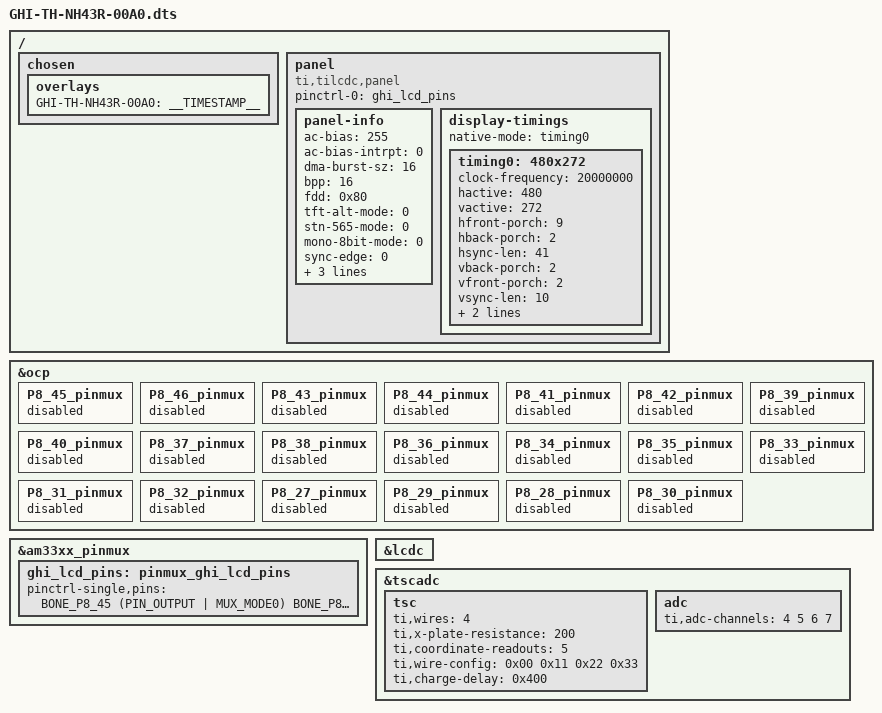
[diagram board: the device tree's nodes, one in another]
/*
 * Copyright (C) 2012 Texas Instruments Incorporated - http://www.ti.com/
 * Copyright (C) 2016 GHI Electronics, LLC - http://www.ghielectronics.com/ 
 *
 * This program is free software; you can redistribute it and/or modify
 * it under the terms of the GNU General Public License version 2 as
 * published by the Free Software Foundation.
 */

/dts-v1/;
/plugin/;

#include <dt-bindings/gpio/gpio.h>
#include <dt-bindings/pinctrl/am33xx.h>
#include <dt-bindings/board/am335x-bbw-bbb-base.h>

/ {
	/*
	 * Helper to show loaded overlays under: /proc/device-tree/chosen/overlays/
	 */
	fragment@0 {
		target-path="/";
		__overlay__ {

			chosen {
				overlays {
					GHI-TH-NH43R-00A0 = __TIMESTAMP__;
				};
			};
		};
	};

	/*
	 * Free up the pins used by the cape from the pinmux helpers.
	 */
	fragment@1 {
		target = <&ocp>;
		__overlay__ {
			P8_45_pinmux { status = "disabled"; };	/* P8_45: lcd_data0.lcd_data0 */
			P8_46_pinmux { status = "disabled"; };	/* P8_46: lcd_data1.lcd_data1 */
			P8_43_pinmux { status = "disabled"; };	/* P8_43: lcd_data2.lcd_data2 */
			P8_44_pinmux { status = "disabled"; };	/* P8_44: lcd_data3.lcd_data3 */
			P8_41_pinmux { status = "disabled"; };	/* P8_41: lcd_data4.lcd_data4 */
			P8_42_pinmux { status = "disabled"; };	/* P8_42: lcd_data5.lcd_data5 */
			P8_39_pinmux { status = "disabled"; };	/* P8_39: lcd_data6.lcd_data6 */
			P8_40_pinmux { status = "disabled"; };	/* P8_40: lcd_data7.lcd_data7 */
			P8_37_pinmux { status = "disabled"; };	/* P8_37: lcd_data8.lcd_data8 */
			P8_38_pinmux { status = "disabled"; };	/* P8_38: lcd_data9.lcd_data9 */
			P8_36_pinmux { status = "disabled"; };	/* P8_36: lcd_data10.lcd_data10 */
			P8_34_pinmux { status = "disabled"; };	/* P8_34: lcd_data11.lcd_data11 */
			P8_35_pinmux { status = "disabled"; };	/* P8_35: lcd_data12.lcd_data12 */
			P8_33_pinmux { status = "disabled"; };	/* P8_33: lcd_data13.lcd_data13 */
			P8_31_pinmux { status = "disabled"; };	/* P8_31: lcd_data14.lcd_data14 */
			P8_32_pinmux { status = "disabled"; };	/* P8_32: lcd_data15.lcd_data15 */

			P8_27_pinmux { status = "disabled"; };	/* P8_27: lcd_vsync.lcd_vsync */
			P8_29_pinmux { status = "disabled"; };	/* P8_29: lcd_hsync.lcd_hsync */
			P8_28_pinmux { status = "disabled"; };	/* P8_28: lcd_pclk.lcd_pclk */
			P8_30_pinmux { status = "disabled"; };	/* P8_30: lcd_ac_bias_en.lcd_ac_bias_en */
		};
	};

	fragment@2 {
		target = <&am33xx_pinmux>;
		__overlay__ {
			ghi_lcd_pins: pinmux_ghi_lcd_pins {
				pinctrl-single,pins = <
					BONE_P8_45 (PIN_OUTPUT | MUX_MODE0)	/* P8_45: lcd_data0.lcd_data0 */
					BONE_P8_46 (PIN_OUTPUT | MUX_MODE0)	/* P8_46: lcd_data1.lcd_data1 */
					BONE_P8_43 (PIN_OUTPUT | MUX_MODE0)	/* P8_43: lcd_data2.lcd_data2 */
					BONE_P8_44 (PIN_OUTPUT | MUX_MODE0)	/* P8_44: lcd_data3.lcd_data3 */
					BONE_P8_41 (PIN_OUTPUT | MUX_MODE0)	/* P8_41: lcd_data4.lcd_data4 */
					BONE_P8_42 (PIN_OUTPUT | MUX_MODE0)	/* P8_42: lcd_data5.lcd_data5 */
					BONE_P8_39 (PIN_OUTPUT | MUX_MODE0)	/* P8_39: lcd_data6.lcd_data6 */
					BONE_P8_40 (PIN_OUTPUT | MUX_MODE0)	/* P8_40: lcd_data7.lcd_data7 */
					BONE_P8_37 (PIN_OUTPUT | MUX_MODE0)	/* P8_37: lcd_data8.lcd_data8 */
					BONE_P8_38 (PIN_OUTPUT | MUX_MODE0)	/* P8_38: lcd_data9.lcd_data9 */
					BONE_P8_36 (PIN_OUTPUT | MUX_MODE0)	/* P8_36: lcd_data10.lcd_data10 */
					BONE_P8_34 (PIN_OUTPUT | MUX_MODE0)	/* P8_34: lcd_data11.lcd_data11 */
					BONE_P8_35 (PIN_OUTPUT | MUX_MODE0)	/* P8_35: lcd_data12.lcd_data12 */
					BONE_P8_33 (PIN_OUTPUT | MUX_MODE0)	/* P8_33: lcd_data13.lcd_data13 */
					BONE_P8_31 (PIN_OUTPUT | MUX_MODE0)	/* P8_31: lcd_data14.lcd_data14 */
					BONE_P8_32 (PIN_OUTPUT | MUX_MODE0)	/* P8_32: lcd_data15.lcd_data15 */

					BONE_P8_27 (PIN_OUTPUT | MUX_MODE0)	/* P8_27: lcd_vsync.lcd_vsync */
					BONE_P8_29 (PIN_OUTPUT | MUX_MODE0)	/* P8_29: lcd_hsync.lcd_hsync */
					BONE_P8_28 (PIN_OUTPUT | MUX_MODE0)	/* P8_28: lcd_pclk.lcd_pclk */
					BONE_P8_30 (PIN_OUTPUT | MUX_MODE0)	/* P8_30: lcd_ac_bias_en.lcd_ac_bias_en */
				>;
			};
		};
	};

	fragment@3 {
		target = <&lcdc>;
		__overlay__ {
			status = "okay";
		};
	};

	fragment@4 {
		target-path="/";
		__overlay__ {
			panel {
				status = "okay";
				compatible = "ti,tilcdc,panel";
				pinctrl-names = "default";
				pinctrl-0 = <&ghi_lcd_pins>;
				panel-info {
					ac-bias           = <255>;
					ac-bias-intrpt    = <0>;
					dma-burst-sz      = <16>;
					bpp               = <16>;
					fdd               = <0x80>;
					tft-alt-mode      = <0>;
					stn-565-mode      = <0>;
					mono-8bit-mode    = <0>;
					sync-edge         = <0>;
					sync-ctrl         = <1>;
					raster-order      = <0>;
					fifo-th           = <0>;
				};
				display-timings {
					native-mode = <&timing0>;
					timing0: 480x272 {
						clock-frequency = <20000000>;
						hactive = <480>;
						vactive = <272>;
						hfront-porch = <9>;
						hback-porch = <2>;
						hsync-len = <41>;
						vback-porch = <2>;
						vfront-porch = <2>;
						vsync-len = <10>;
						hsync-active = <0>;
						vsync-active  = <0>;
					};
				};
			};
		};
	};

	fragment@5 {
		target = <&tscadc>;
		__overlay__ {

			status = "okay";
			tsc {
				ti,wires = <4>;
				ti,x-plate-resistance = <200>;
				ti,coordinate-readouts = <5>;
				ti,wire-config = <0x00 0x11 0x22 0x33>;
				ti,charge-delay = <0x400>;
			};

			adc {
				ti,adc-channels = <4 5 6 7>;
			};
		};
	};
};
